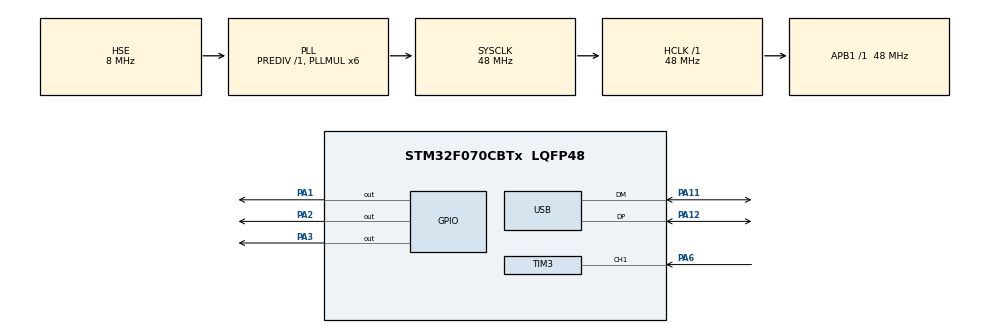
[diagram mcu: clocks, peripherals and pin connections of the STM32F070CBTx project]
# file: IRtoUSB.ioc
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Mcu.Family=STM32F0
Mcu.Name=STM32F070CBTx
Mcu.Package=LQFP48
NVIC.USB_IRQn=true\:0\:0\:false\:false\:true
PA1.PinState=GPIO_PIN_SET
PA1.Signal=GPIO_Output
PA11.Mode=Device
PA11.Signal=USB_DM
PA12.Mode=Device
PA12.Signal=USB_DP
PA2.PinState=GPIO_PIN_SET
PA2.Signal=GPIO_Output
PA3.PinState=GPIO_PIN_SET
PA3.Signal=GPIO_Output
PA6.Signal=S_TIM3_CH1
PF0-OSC_IN.Mode=HSE-External-Oscillator
PF0-OSC_IN.Signal=RCC_OSC_IN
PF1-OSC_OUT.Mode=HSE-External-Oscillator
PF1-OSC_OUT.Signal=RCC_OSC_OUT
ProjectManager.HeapSize=0x200
ProjectManager.StackSize=0x400
ProjectManager.TargetToolchain=MDK-ARM V5
RCC.AHBFreq_Value=48000000
RCC.APB1Freq_Value=48000000
RCC.APB1TimFreq_Value=48000000
RCC.EnbaleCSS=true
RCC.HCLKFreq_Value=48000000
RCC.HSIState=RCC_HSI_ON
RCC.PLLMUL=RCC_PLL_MUL6
RCC.PLLSourceVirtual=RCC_PLLSOURCE_HSE
RCC.SYSCLKFreq_VALUE=48000000
RCC.SYSCLKSource=RCC_SYSCLKSOURCE_PLLCLK
SH.S_TIM3_CH1.0=TIM3_CH1,TriggerSource_TI1ED
USB_DEVICE.MANUFACTURER_STRING=DenisTyurin
USB_DEVICE.PID_HID_FS=1025
USB_DEVICE.PRODUCT_STRING_HID_FS=STM32 based IR to Keyboard adapter
USB_DEVICE.USBD_HandleTypeDef=hUsbDeviceFS
USB_DEVICE.VID=8263
USB_DEVICE.VirtualMode=Hid
USB_DEVICE.VirtualModeFS=Hid_FS
VP_TIM3_VS_CH1.Mode=Input_Capture1_from_TRC
VP_TIM3_VS_ClockSourceINT.Mode=Internal
VP_USB_DEVICE_VS_USB_DEVICE_HID_FS.Mode=HID_FS
board=IRtoUSB

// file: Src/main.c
/**
  ******************************************************************************
  * File Name          : main.c
  * Description        : Main program body
  ******************************************************************************
  *
  * COPYRIGHT(c) 2016 STMicroelectronics
  *
  * Redistribution and use in source and binary forms, with or without modification,
  * are permitted provided that the following conditions are met:
  *   1. Redistributions of source code must retain the above copyright notice,
  *      this list of conditions and the following disclaimer.
  *   2. Redistributions in binary form must reproduce the above copyright notice,
  *      this list of conditions and the following disclaimer in the documentation
  *      and/or other materials provided with the distribution.
  *   3. Neither the name of STMicroelectronics nor the names of its contributors
  *      may be used to endorse or promote products derived from this software
  *      without specific prior written permission.
  *
  * THIS SOFTWARE IS PROVIDED BY THE COPYRIGHT HOLDERS AND CONTRIBUTORS "AS IS"
  * AND ANY EXPRESS OR IMPLIED WARRANTIES, INCLUDING, BUT NOT LIMITED TO, THE
  * IMPLIED WARRANTIES OF MERCHANTABILITY AND FITNESS FOR A PARTICULAR PURPOSE ARE
  * DISCLAIMED. IN NO EVENT SHALL THE COPYRIGHT HOLDER OR CONTRIBUTORS BE LIABLE
  * FOR ANY DIRECT, INDIRECT, INCIDENTAL, SPECIAL, EXEMPLARY, OR CONSEQUENTIAL
  * DAMAGES (INCLUDING, BUT NOT LIMITED TO, PROCUREMENT OF SUBSTITUTE GOODS OR
  * SERVICES; LOSS OF USE, DATA, OR PROFITS; OR BUSINESS INTERRUPTION) HOWEVER
  * CAUSED AND ON ANY THEORY OF LIABILITY, WHETHER IN CONTRACT, STRICT LIABILITY,
  * OR TORT (INCLUDING NEGLIGENCE OR OTHERWISE) ARISING IN ANY WAY OUT OF THE USE
  * OF THIS SOFTWARE, EVEN IF ADVISED OF THE POSSIBILITY OF SUCH DAMAGE.
  *
  ******************************************************************************
  */
#include "stm32f0xx_hal.h"
#include "usb_device.h"

TIM_HandleTypeDef htim3;

/* USER CODE BEGIN PV */
/* Private variables ---------------------------------------------------------*/

/* USER CODE END PV */

void SystemClock_Config(void);
static void MX_GPIO_Init(void);
static void MX_TIM3_Init(void);

/* USER CODE BEGIN PFP */
/* Private function prototypes -----------------------------------------------*/

/* USER CODE END PFP */

/* USER CODE BEGIN 0 */
#define NUM_CYCLES_US 22
#define NUM_CYCLES_MS NUM_CYCLES_US*1000
#define delay_ms(ms)            _delay_(((ms)*(NUM_CYCLES_MS)))
#define delay_us(us)            _delay_(((us)*(NUM_CYCLES_US)))

volatile void _delay_ (uint32_t delay)
{
    while(delay--);
}
/* USER CODE END 0 */

int main(void)
{
	USB_HIDDEVICE_Keyboard_t Keyboard_Data;

  /* MCU Configuration----------------------------------------------------------*/

  /* Reset of all peripherals, Initializes the Flash interface and the Systick. */
  HAL_Init();

  /* Configure the system clock */
  SystemClock_Config();

  /* Initialize all configured peripherals */
  MX_GPIO_Init();
  MX_TIM3_Init();
  MX_USB_DEVICE_Init();

  /* Infinite loop */
  /* USER CODE BEGIN WHILE */

	delay_ms(1000);
//	MX_USB_DEVICE_SendHIDAction(0x01);
	USB_HIDDEVICE_KeyboardStructInit(&Keyboard_Data);

	Keyboard_Data.Key1 = 0x01;

	USB_HIDDEVICE_KeyboardSend(&Keyboard_Data);

  while (1)
  {
  /* USER CODE END WHILE */

  }

}

/** System Clock Configuration
*/
void SystemClock_Config(void)
{

  RCC_OscInitTypeDef RCC_OscInitStruct;
  RCC_ClkInitTypeDef RCC_ClkInitStruct;
  RCC_PeriphCLKInitTypeDef PeriphClkInit;

  RCC_OscInitStruct.OscillatorType = RCC_OSCILLATORTYPE_HSE;
  RCC_OscInitStruct.HSEState = RCC_HSE_ON;
  RCC_OscInitStruct.PLL.PLLState = RCC_PLL_ON;
  RCC_OscInitStruct.PLL.PLLSource = RCC_PLLSOURCE_HSE;
  RCC_OscInitStruct.PLL.PLLMUL = RCC_PLL_MUL6;
  RCC_OscInitStruct.PLL.PREDIV = RCC_PREDIV_DIV1;
  HAL_RCC_OscConfig(&RCC_OscInitStruct);

  RCC_ClkInitStruct.ClockType = RCC_CLOCKTYPE_HCLK|RCC_CLOCKTYPE_SYSCLK
                              |RCC_CLOCKTYPE_PCLK1;
  RCC_ClkInitStruct.SYSCLKSource = RCC_SYSCLKSOURCE_PLLCLK;
  RCC_ClkInitStruct.AHBCLKDivider = RCC_SYSCLK_DIV1;
  RCC_ClkInitStruct.APB1CLKDivider = RCC_HCLK_DIV1;
  HAL_RCC_ClockConfig(&RCC_ClkInitStruct, FLASH_LATENCY_1);

  PeriphClkInit.PeriphClockSelection = RCC_PERIPHCLK_USB;
  PeriphClkInit.UsbClockSelection = RCC_USBCLKSOURCE_PLL;
  HAL_RCCEx_PeriphCLKConfig(&PeriphClkInit);

  HAL_RCC_EnableCSS();

  HAL_SYSTICK_Config(HAL_RCC_GetHCLKFreq()/1000);

  HAL_SYSTICK_CLKSourceConfig(SYSTICK_CLKSOURCE_HCLK);

  /* SysTick_IRQn interrupt configuration */
  HAL_NVIC_SetPriority(SysTick_IRQn, 0, 0);
}

/* TIM3 init function */
void MX_TIM3_Init(void)
{

  TIM_ClockConfigTypeDef sClockSourceConfig;
  TIM_SlaveConfigTypeDef sSlaveConfig;
  TIM_MasterConfigTypeDef sMasterConfig;
  TIM_IC_InitTypeDef sConfigIC;

  htim3.Instance = TIM3;
  htim3.Init.Prescaler = 0;
  htim3.Init.CounterMode = TIM_COUNTERMODE_UP;
  htim3.Init.Period = 0;
  htim3.Init.ClockDivision = TIM_CLOCKDIVISION_DIV1;
  HAL_TIM_Base_Init(&htim3);

  sClockSourceConfig.ClockSource = TIM_CLOCKSOURCE_INTERNAL;
  HAL_TIM_ConfigClockSource(&htim3, &sClockSourceConfig);

  HAL_TIM_IC_Init(&htim3);

  sSlaveConfig.SlaveMode = TIM_SLAVEMODE_DISABLE;
  sSlaveConfig.InputTrigger = TIM_TS_TI1F_ED;
  sSlaveConfig.TriggerFilter = 0;
  HAL_TIM_SlaveConfigSynchronization(&htim3, &sSlaveConfig);

  sMasterConfig.MasterOutputTrigger = TIM_TRGO_RESET;
  sMasterConfig.MasterSlaveMode = TIM_MASTERSLAVEMODE_DISABLE;
  HAL_TIMEx_MasterConfigSynchronization(&htim3, &sMasterConfig);

  sConfigIC.ICPolarity = TIM_INPUTCHANNELPOLARITY_RISING;
  sConfigIC.ICSelection = TIM_ICSELECTION_TRC;
  sConfigIC.ICPrescaler = TIM_ICPSC_DIV1;
  sConfigIC.ICFilter = 0;
  HAL_TIM_IC_ConfigChannel(&htim3, &sConfigIC, TIM_CHANNEL_1);

}

/** Configure pins as
        * Analog
        * Input
        * Output
        * EVENT_OUT
        * EXTI
*/
void MX_GPIO_Init(void)
{

  GPIO_InitTypeDef GPIO_InitStruct;

  /* GPIO Ports Clock Enable */
  __HAL_RCC_GPIOF_CLK_ENABLE();
  __HAL_RCC_GPIOA_CLK_ENABLE();

  /*Configure GPIO pin Output Level */
  HAL_GPIO_WritePin(GPIOA, GPIO_PIN_1|GPIO_PIN_2|GPIO_PIN_3, GPIO_PIN_SET);

  /*Configure GPIO pins : PA1 PA2 PA3 */
  GPIO_InitStruct.Pin = GPIO_PIN_1|GPIO_PIN_2|GPIO_PIN_3;
  GPIO_InitStruct.Mode = GPIO_MODE_OUTPUT_PP;
  GPIO_InitStruct.Pull = GPIO_NOPULL;
  GPIO_InitStruct.Speed = GPIO_SPEED_FREQ_LOW;
  HAL_GPIO_Init(GPIOA, &GPIO_InitStruct);

}

/************************ (C) COPYRIGHT STMicroelectronics *****END OF FILE****/
